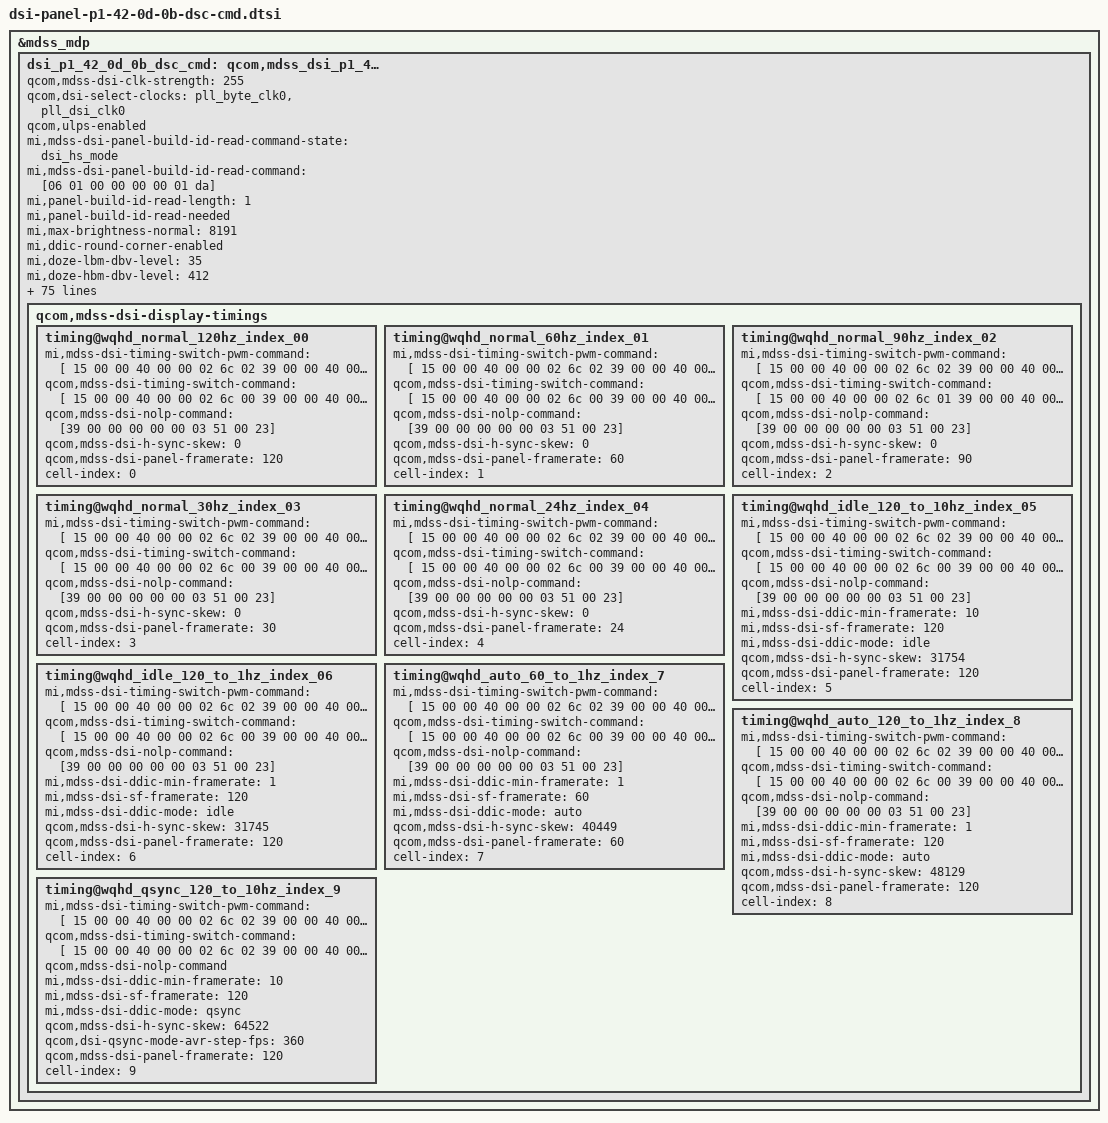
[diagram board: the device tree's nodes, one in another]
/* Xiaomi 17 Ultra panel configuration, OS4.0.7.0.XPACNXM. */

&mdss_mdp {
	dsi_p1_42_0d_0b_dsc_cmd: qcom,mdss_dsi_p1_42_0d_0b_dsc_cmd {
		qcom,mdss-dsi-clk-strength = <255>;
		qcom,dsi-select-clocks = "pll_byte_clk0", "pll_dsi_clk0";
		qcom,ulps-enabled;
		mi,mdss-dsi-panel-build-id-read-command-state = "dsi_hs_mode";
		mi,mdss-dsi-panel-build-id-read-command = [06 01 00 00 00 00 01 da];
		mi,panel-build-id-read-length = <1>;
		mi,panel-build-id-read-needed;
		mi,max-brightness-normal = <8191>;
		mi,ddic-round-corner-enabled;
		mi,doze-lbm-dbv-level = <35>;
		mi,doze-hbm-dbv-level = <412>;
		mi,mdss-dsi-panel-flatmode-on-status-value = <0>;
		mi,mdss-dsi-panel-flatmode-status-read-length = <1>;
		mi,mdss-dsi-panel-flatmode-status-command-state = "dsi_hs_mode";
		mi,mdss-dsi-panel-flatmode-status-command = [06 01 00 01 00 00 01 5f];
		mi,flatmode-status-check-enabled;
		mi,mdss-fac-brightness-max-level = <8191>;
		mi,mdss-dsi-fac-bl-max-level = <8191>;
		mi,mdss-dsi-panel-cell-id-read-length = <13>;
		mi,mdss-dsi-panel-cell-id-read-command-state = "dsi_hs_mode";
		mi,mdss-dsi-panel-cell-id-read-command = [06 01 00 00 00 00 01 5a];
		mi,mdss-dsi-panel-wp-read-length = <8>;
		mi,mdss-dsi-panel-wp-read-command-state = "dsi_hs_mode";
		mi,mdss-dsi-panel-wp-read-command = [06 01 00 00 00 00 01 5c];
		mi,esd-err-irq-gpio-flag = <8196>;
		mi,esd-err-irq-gpio = <&tlmm 97 8196>;
		mi,default-dc-flag;
		mi,dc-feature-enabled;
		mi,panel-on-dimming-delay = <120>;
		mi,dsi-panel-backplane-technology = "LTPO";
		mi,panel-id = <20529 4328715>;
		qcom,platform-pmic-reset-gpio = <&tlmm 171 0>;
		qcom,platform-reset-gpio = <&tlmm 98 0>;
		qcom,mdss-brightness-init-level = <916>;
		qcom,mdss-brightness-max-level = <16383>;
		qcom,bl-dsc-cmd-state = "dsi_hs_mode";
		qcom,mdss-dsi-bl-max-level = <16383>;
		qcom,mdss-dsi-bl-min-level = <7>;
		qcom,mdss-dsi-bl-pmic-control-type = "bl_ctrl_dcs";
		qcom,panel-supply-entries = <&dsi_panel_pwr_supply_p1_0b>;
		qcom,mdss-disable-cesta-hw-sleep;
		qcom,mdss-dsi-dma-schedule-window = <50>;
		qcom,mdss-dsi-dma-schedule-line = <1>;
		qcom,mdss-dsi-panel-blackness-level = <3230>;
		qcom,mdss-dsi-panel-peak-brightness = <32000000>;
		qcom,mdss-dsi-panel-hdr-color-primaries = <14500 15500 32000 17000 15500 30000 8000 3000>;
		qcom,mdss-dsi-panel-hdr-enabled;
		qcom,bl-update-flag = "delay_until_first_frame";
		qcom,mdss-dsi-bl-inverted-dbv;
		qcom,mdss-dsi-lp11-init;
		qcom,mdss-dsi-tx-eot-append;
		qcom,mdss-dsi-te-dcs-command = <1>;
		qcom,mdss-dsi-wr-mem-continue = <60>;
		qcom,mdss-dsi-wr-mem-start = <44>;
		qcom,mdss-dsi-te-pin-select = <1>;
		qcom,mdss-pan-physical-height-dimension = <1580>;
		qcom,mdss-pan-physical-width-dimension = <727>;
		qcom,mdss-dsi-reset-sequence = <1 1 0 1 1 10>;
		qcom,mdss-dsi-mdp-trigger = "none";
		qcom,mdss-dsi-dma-trigger = "trigger_sw";
		qcom,mdss-dsi-color-order = "rgb_swap_rgb";
		qcom,mdss-dsi-lane-3-state;
		qcom,mdss-dsi-lane-2-state;
		qcom,mdss-dsi-lane-1-state;
		qcom,mdss-dsi-lane-0-state;
		qcom,mdss-dsi-bllp-power-mode;
		qcom,mdss-dsi-bllp-eof-power-mode;
		qcom,mdss-dsi-traffic-mode = "burst_mode";
		qcom,dsi-phy-num = <0>;
		qcom,dsi-ctrl-num = <0>;
		qcom,mdss-dsi-bpp = <30>;
		qcom,mdss-dsi-virtual-channel-id = <0>;
		qcom,mdss-dsi-panel-physical-type = "oled";
		qcom,mdss-dsi-panel-type = "dsi_cmd_mode";
		qcom,mdss-dsi-panel-name = "xiaomi p1 42 0d 0b prim cmd mode dsc dsi panel";

		qcom,mdss-dsi-display-timings {
			timing@wqhd_normal_120hz_index_00 {
				#include "dsi-panel-p1-42-0d-0b-dsc-cmd-common.dtsi"
				mi,mdss-dsi-timing-switch-pwm-command = [
					15 00 00 40 00 00 02 6c 02 39 00 00 40 00 00 03
					75 00 00 39 00 00 40 00 00 04 71 00 00 00 39 00
					00 40 00 00 03 f0 aa 16 15 00 00 40 00 00 02 d0
					00 15 00 00 40 00 00 02 65 07 15 00 00 40 00 00
					02 d1 02 15 00 00 40 00 00 02 d2 01 15 00 00 40
					00 00 02 65 02 39 00 00 40 00 00 04 d2 03 65 0f
					15 00 00 40 00 00 02 76 01 15 00 00 40 00 00 02
					77 05 39 00 00 40 00 00 03 f0 aa 10 15 00 00 40
					00 00 02 cf 09 39 00 00 00 00 00 03 f0 aa 00
				];
				qcom,mdss-dsi-timing-switch-command = [
					15 00 00 40 00 00 02 6c 00 39 00 00 40 00 00 03
					75 00 00 39 00 00 40 00 00 04 71 00 00 00 39 00
					00 40 00 00 03 f0 aa 16 15 00 00 40 00 00 02 d0
					00 15 00 00 40 00 00 02 65 01 15 00 00 40 00 00
					02 d1 00 15 00 00 40 00 00 02 d2 01 15 00 00 40
					00 00 02 76 00 15 00 00 40 00 00 02 77 00 39 00
					00 40 00 00 03 f0 aa 10 15 00 00 40 00 00 02 cf
					17 39 00 00 00 00 00 03 f0 aa 00
				];
				qcom,mdss-dsi-nolp-command = [39 00 00 00 00 00 03 51 00 23];
				qcom,mdss-dsi-h-sync-skew = <0>;
				qcom,mdss-dsi-panel-framerate = <120>;
				cell-index = <0>;
			};

			timing@wqhd_normal_60hz_index_01 {
				#include "dsi-panel-p1-42-0d-0b-dsc-cmd-common.dtsi"
				mi,mdss-dsi-timing-switch-pwm-command = [
					15 00 00 40 00 00 02 6c 02 39 00 00 40 00 00 03
					75 c0 00 39 00 00 40 00 00 04 71 01 00 01 39 00
					00 40 00 00 03 f0 aa 16 15 00 00 40 00 00 02 d0
					00 15 00 00 40 00 00 02 65 07 15 00 00 40 00 00
					02 d1 02 15 00 00 40 00 00 02 d2 01 15 00 00 40
					00 00 02 65 02 39 00 00 40 00 00 04 d2 03 65 0f
					15 00 00 40 00 00 02 76 01 15 00 00 40 00 00 02
					77 0b 39 00 00 40 00 00 03 f0 aa 10 15 00 00 40
					00 00 02 cf 09 39 00 00 00 00 00 03 f0 aa 00
				];
				qcom,mdss-dsi-timing-switch-command = [
					15 00 00 40 00 00 02 6c 00 39 00 00 40 00 00 03
					75 c0 00 39 00 00 40 00 00 04 71 01 00 01 39 00
					00 40 00 00 03 f0 aa 16 15 00 00 40 00 00 02 d0
					00 15 00 00 40 00 00 02 65 01 15 00 00 40 00 00
					02 d1 00 15 00 00 40 00 00 02 d2 01 15 00 00 40
					00 00 02 65 02 39 00 00 40 00 00 04 d2 0a 53 0f
					15 00 00 40 00 00 02 76 01 15 00 00 40 00 00 02
					77 03 39 00 00 40 00 00 03 f0 aa 10 15 00 00 40
					00 00 02 cf 09 39 00 00 00 00 00 03 f0 aa 00
				];
				qcom,mdss-dsi-nolp-command = [39 00 00 00 00 00 03 51 00 23];
				qcom,mdss-dsi-h-sync-skew = <0>;
				qcom,mdss-dsi-panel-framerate = <60>;
				cell-index = <1>;
			};

			timing@wqhd_normal_90hz_index_02 {
				#include "dsi-panel-p1-42-0d-0b-dsc-cmd-common.dtsi"
				mi,mdss-dsi-timing-switch-pwm-command = [
					15 00 00 40 00 00 02 6c 02 39 00 00 40 00 00 03
					75 c0 00 39 00 00 40 00 00 04 71 01 10 00 39 00
					00 40 00 00 03 f0 aa 16 15 00 00 40 00 00 02 d0
					00 15 00 00 40 00 00 02 65 07 15 00 00 40 00 00
					02 d1 02 15 00 00 40 00 00 02 d2 01 15 00 00 40
					00 00 02 65 02 39 00 00 40 00 00 04 d2 03 65 0f
					15 00 00 40 00 00 02 76 01 15 00 00 40 00 00 02
					77 07 39 00 00 40 00 00 03 f0 aa 10 15 00 00 40
					00 00 02 cf 09 39 00 00 00 00 00 03 f0 aa 00
				];
				qcom,mdss-dsi-timing-switch-command = [
					15 00 00 40 00 00 02 6c 01 39 00 00 40 00 00 03
					75 c0 06 39 00 00 40 00 00 04 71 00 00 00 39 00
					00 40 00 00 03 f0 aa 16 15 00 00 40 00 00 02 d0
					03 15 00 00 40 00 00 02 65 04 15 00 00 40 00 00
					02 d1 02 15 00 00 40 00 00 02 d2 01 15 00 00 40
					00 00 02 65 02 39 00 00 40 00 00 04 d2 0d ca 0f
					15 00 00 40 00 00 02 76 01 15 00 00 40 00 00 02
					77 01 39 00 00 40 00 00 03 f0 aa 10 15 00 00 40
					00 00 02 cf 09 39 00 00 00 00 00 03 f0 aa 00
				];
				qcom,mdss-dsi-nolp-command = [39 00 00 00 00 00 03 51 00 23];
				qcom,mdss-dsi-h-sync-skew = <0>;
				qcom,mdss-dsi-panel-framerate = <90>;
				cell-index = <2>;
			};

			timing@wqhd_normal_30hz_index_03 {
				#include "dsi-panel-p1-42-0d-0b-dsc-cmd-common.dtsi"
				mi,mdss-dsi-timing-switch-pwm-command = [
					15 00 00 40 00 00 02 6c 02 39 00 00 40 00 00 03
					75 c0 01 39 00 00 40 00 00 04 71 00 00 00 39 00
					00 40 00 00 03 f0 aa 16 15 00 00 40 00 00 02 d0
					00 15 00 00 40 00 00 02 65 07 15 00 00 40 00 00
					02 d1 05 15 00 00 40 00 00 02 d2 01 15 00 00 40
					00 00 02 65 02 39 00 00 40 00 00 04 d2 03 65 0f
					15 00 00 40 00 00 02 76 01 15 00 00 40 00 00 02
					77 17 39 00 00 40 00 00 03 f0 aa 10 15 00 00 40
					00 00 02 cf 09 39 00 00 00 00 00 03 f0 aa 00
				];
				qcom,mdss-dsi-timing-switch-command = [
					15 00 00 40 00 00 02 6c 00 39 00 00 40 00 00 03
					75 c0 01 39 00 00 40 00 00 04 71 00 00 00 39 00
					00 40 00 00 03 f0 aa 16 15 00 00 40 00 00 02 d0
					00 15 00 00 40 00 00 02 65 01 15 00 00 40 00 00
					02 d1 01 15 00 00 40 00 00 02 d2 01 15 00 00 40
					00 00 02 65 02 39 00 00 40 00 00 04 d2 0a 53 0f
					15 00 00 40 00 00 02 76 01 15 00 00 40 00 00 02
					77 07 39 00 00 40 00 00 03 f0 aa 10 15 00 00 40
					00 00 02 cf 09 39 00 00 00 00 00 03 f0 aa 00
				];
				qcom,mdss-dsi-nolp-command = [39 00 00 00 00 00 03 51 00 23];
				qcom,mdss-dsi-h-sync-skew = <0>;
				qcom,mdss-dsi-panel-framerate = <30>;
				cell-index = <3>;
			};

			timing@wqhd_normal_24hz_index_04 {
				#include "dsi-panel-p1-42-0d-0b-dsc-cmd-common.dtsi"
				mi,mdss-dsi-timing-switch-pwm-command = [
					15 00 00 40 00 00 02 6c 02 39 00 00 40 00 00 03
					75 c0 02 39 00 00 40 00 00 04 71 00 00 00 39 00
					00 40 00 00 03 f0 aa 16 15 00 00 40 00 00 02 d0
					00 15 00 00 40 00 00 02 65 07 15 00 00 40 00 00
					02 d1 0b 15 00 00 40 00 00 02 d2 01 15 00 00 40
					00 00 02 65 02 39 00 00 40 00 00 04 d2 03 65 0f
					15 00 00 40 00 00 02 76 01 15 00 00 40 00 00 02
					77 1d 39 00 00 40 00 00 03 f0 aa 10 15 00 00 40
					00 00 02 cf 09 39 00 00 00 00 00 03 f0 aa 00
				];
				qcom,mdss-dsi-timing-switch-command = [
					15 00 00 40 00 00 02 6c 00 39 00 00 40 00 00 03
					75 c0 02 39 00 00 40 00 00 04 71 00 00 00 39 00
					00 40 00 00 03 f0 aa 16 15 00 00 40 00 00 02 d0
					00 15 00 00 40 00 00 02 65 01 15 00 00 40 00 00
					02 d1 01 15 00 00 40 00 00 02 d2 01 15 00 00 40
					00 00 02 65 02 39 00 00 40 00 00 04 d2 0a 53 0f
					15 00 00 40 00 00 02 76 01 15 00 00 40 00 00 02
					77 09 39 00 00 40 00 00 03 f0 aa 10 15 00 00 40
					00 00 02 cf 09 39 00 00 00 00 00 03 f0 aa 00
				];
				qcom,mdss-dsi-nolp-command = [39 00 00 00 00 00 03 51 00 23];
				qcom,mdss-dsi-h-sync-skew = <0>;
				qcom,mdss-dsi-panel-framerate = <24>;
				cell-index = <4>;
			};

			timing@wqhd_idle_120_to_10hz_index_05 {
				#include "dsi-panel-p1-42-0d-0b-dsc-cmd-common.dtsi"
				mi,mdss-dsi-timing-switch-pwm-command = [
					15 00 00 40 00 00 02 6c 02 39 00 00 40 00 00 03
					75 c0 07 39 00 00 40 00 00 04 71 00 00 00 39 00
					00 40 00 00 03 f0 aa 16 15 00 00 40 00 00 02 d0
					03 15 00 00 40 00 00 02 65 07 15 00 00 40 00 00
					02 d1 0b 15 00 00 40 00 00 02 d2 01 15 00 00 40
					00 00 02 65 02 39 00 00 40 00 00 04 d2 03 65 0f
					15 00 00 40 00 00 02 76 01 15 00 00 40 00 00 02
					77 05 39 00 00 40 00 00 03 f0 aa 10 15 00 00 40
					00 00 02 cf 09 39 00 00 00 00 00 03 f0 aa 00
				];
				qcom,mdss-dsi-timing-switch-command = [
					15 00 00 40 00 00 02 6c 00 39 00 00 40 00 00 03
					75 c0 03 39 00 00 40 00 00 04 71 00 00 00 39 00
					00 40 00 00 03 f0 aa 16 15 00 00 40 00 00 02 d0
					03 15 00 00 40 00 00 02 65 01 15 00 00 40 00 00
					02 d1 01 15 00 00 40 00 00 02 d2 01 15 00 00 40
					00 00 02 65 02 39 00 00 40 00 00 04 d2 0a 53 0f
					15 00 00 40 00 00 02 76 01 15 00 00 40 00 00 02
					77 01 39 00 00 40 00 00 03 f0 aa 10 15 00 00 40
					00 00 02 cf 09 39 00 00 00 00 00 03 f0 aa 00
				];
				qcom,mdss-dsi-nolp-command = [39 00 00 00 00 00 03 51 00 23];
				mi,mdss-dsi-ddic-min-framerate = <10>;
				mi,mdss-dsi-sf-framerate = <120>;
				mi,mdss-dsi-ddic-mode = "idle";
				qcom,mdss-dsi-h-sync-skew = <31754>;
				qcom,mdss-dsi-panel-framerate = <120>;
				cell-index = <5>;
			};

			timing@wqhd_idle_120_to_1hz_index_06 {
				#include "dsi-panel-p1-42-0d-0b-dsc-cmd-common.dtsi"
				mi,mdss-dsi-timing-switch-pwm-command = [
					15 00 00 40 00 00 02 6c 02 39 00 00 40 00 00 03
					75 c0 05 39 00 00 40 00 00 04 71 00 00 00 39 00
					00 40 00 00 03 f0 aa 16 15 00 00 40 00 00 02 d0
					03 15 00 00 40 00 00 02 65 07 15 00 00 40 00 00
					02 d1 0b 15 00 00 40 00 00 02 d2 01 15 00 00 40
					00 00 02 65 02 39 00 00 40 00 00 04 d2 03 65 0f
					15 00 00 40 00 00 02 76 01 15 00 00 40 00 00 02
					77 05 39 00 00 40 00 00 03 f0 aa 10 15 00 00 40
					00 00 02 cf 09 39 00 00 00 00 00 03 f0 aa 00
				];
				qcom,mdss-dsi-timing-switch-command = [
					15 00 00 40 00 00 02 6c 00 39 00 00 40 00 00 03
					75 c0 04 39 00 00 40 00 00 04 71 00 00 00 39 00
					00 40 00 00 03 f0 aa 16 15 00 00 40 00 00 02 d0
					03 15 00 00 40 00 00 02 65 01 15 00 00 40 00 00
					02 d1 01 15 00 00 40 00 00 02 d2 01 15 00 00 40
					00 00 02 65 02 39 00 00 40 00 00 04 d2 0a 53 0f
					15 00 00 40 00 00 02 76 01 15 00 00 40 00 00 02
					77 01 39 00 00 40 00 00 03 f0 aa 10 15 00 00 40
					00 00 02 cf 09 39 00 00 00 00 00 03 f0 aa 00
				];
				qcom,mdss-dsi-nolp-command = [39 00 00 00 00 00 03 51 00 23];
				mi,mdss-dsi-ddic-min-framerate = <1>;
				mi,mdss-dsi-sf-framerate = <120>;
				mi,mdss-dsi-ddic-mode = "idle";
				qcom,mdss-dsi-h-sync-skew = <31745>;
				qcom,mdss-dsi-panel-framerate = <120>;
				cell-index = <6>;
			};

			timing@wqhd_auto_60_to_1hz_index_7 {
				#include "dsi-panel-p1-42-0d-0b-dsc-cmd-common.dtsi"
				mi,mdss-dsi-timing-switch-pwm-command = [
					15 00 00 40 00 00 02 6c 02 39 00 00 40 00 00 03
					75 c0 05 39 00 00 40 00 00 04 71 00 00 00 39 00
					00 40 00 00 03 f0 aa 16 15 00 00 40 00 00 02 d0
					01 15 00 00 40 00 00 02 65 07 15 00 00 40 00 00
					02 d1 0b 15 00 00 40 00 00 02 d2 01 15 00 00 40
					00 00 02 65 02 39 00 00 40 00 00 04 d2 03 65 0f
					15 00 00 40 00 00 02 76 01 15 00 00 40 00 00 02
					77 0b 39 00 00 40 00 00 03 f0 aa 10 15 00 00 40
					00 00 02 cf 09 39 00 00 00 00 00 03 f0 aa 00
				];
				qcom,mdss-dsi-timing-switch-command = [
					15 00 00 40 00 00 02 6c 00 39 00 00 40 00 00 03
					75 c0 05 39 00 00 40 00 00 04 71 00 00 00 39 00
					00 40 00 00 03 f0 aa 16 15 00 00 40 00 00 02 d0
					01 15 00 00 40 00 00 02 65 01 15 00 00 40 00 00
					02 d1 03 15 00 00 40 00 00 02 d2 01 15 00 00 40
					00 00 02 65 02 39 00 00 40 00 00 04 d2 0a 53 0f
					15 00 00 40 00 00 02 76 01 15 00 00 40 00 00 02
					77 03 39 00 00 40 00 00 03 f0 aa 10 15 00 00 40
					00 00 02 cf 09 39 00 00 00 00 00 03 f0 aa 00
				];
				qcom,mdss-dsi-nolp-command = [39 00 00 00 00 00 03 51 00 23];
				mi,mdss-dsi-ddic-min-framerate = <1>;
				mi,mdss-dsi-sf-framerate = <60>;
				mi,mdss-dsi-ddic-mode = "auto";
				qcom,mdss-dsi-h-sync-skew = <40449>;
				qcom,mdss-dsi-panel-framerate = <60>;
				cell-index = <7>;
			};

			timing@wqhd_auto_120_to_1hz_index_8 {
				#include "dsi-panel-p1-42-0d-0b-dsc-cmd-common.dtsi"
				mi,mdss-dsi-timing-switch-pwm-command = [
					15 00 00 40 00 00 02 6c 02 39 00 00 40 00 00 03
					75 c0 05 39 00 00 40 00 00 04 71 00 00 00 39 00
					00 40 00 00 03 f0 aa 16 15 00 00 40 00 00 02 d0
					03 15 00 00 40 00 00 02 65 07 15 00 00 40 00 00
					02 d1 0b 15 00 00 40 00 00 02 d2 01 15 00 00 40
					00 00 02 65 02 39 00 00 40 00 00 04 d2 03 65 0f
					15 00 00 40 00 00 02 76 01 15 00 00 40 00 00 02
					77 05 39 00 00 40 00 00 03 f0 aa 10 15 00 00 40
					00 00 02 cf 09 39 00 00 00 00 00 03 f0 aa 00
				];
				qcom,mdss-dsi-timing-switch-command = [
					15 00 00 40 00 00 02 6c 00 39 00 00 40 00 00 03
					75 c0 04 39 00 00 40 00 00 04 71 00 00 00 39 00
					00 40 00 00 03 f0 aa 16 15 00 00 40 00 00 02 d0
					03 15 00 00 40 00 00 02 65 01 15 00 00 40 00 00
					02 d1 01 15 00 00 40 00 00 02 d2 01 15 00 00 40
					00 00 02 65 02 39 00 00 40 00 00 04 d2 0a 53 0f
					15 00 00 40 00 00 02 76 01 15 00 00 40 00 00 02
					77 01 39 00 00 40 00 00 03 f0 aa 10 15 00 00 40
					00 00 02 cf 09 39 00 00 00 00 00 03 f0 aa 00
				];
				qcom,mdss-dsi-nolp-command = [39 00 00 00 00 00 03 51 00 23];
				mi,mdss-dsi-ddic-min-framerate = <1>;
				mi,mdss-dsi-sf-framerate = <120>;
				mi,mdss-dsi-ddic-mode = "auto";
				qcom,mdss-dsi-h-sync-skew = <48129>;
				qcom,mdss-dsi-panel-framerate = <120>;
				cell-index = <8>;
			};

			timing@wqhd_qsync_120_to_10hz_index_9 {
				#include "dsi-panel-p1-42-0d-0b-dsc-cmd-common.dtsi"
				mi,mdss-dsi-timing-switch-pwm-command = [
					15 00 00 40 00 00 02 6c 02 39 00 00 40 00 00 03
					75 c0 07 39 00 00 40 00 00 04 71 00 00 00 39 00
					00 40 00 00 03 f0 aa 16 15 00 00 40 00 00 02 d0
					01 15 00 00 40 00 00 02 65 07 15 00 00 40 00 00
					02 d1 0b 15 00 00 40 00 00 02 d2 02 15 00 00 40
					00 00 02 76 00 15 00 00 40 00 00 02 77 00 39 00
					00 40 00 00 03 f0 aa 10 15 00 00 40 00 00 02 cf
					17 39 00 00 00 00 00 03 f0 aa 00
				];
				qcom,mdss-dsi-timing-switch-command = [
					15 00 00 40 00 00 02 6c 02 39 00 00 40 00 00 03
					75 c0 07 39 00 00 40 00 00 04 71 00 00 00 39 00
					00 40 00 00 03 f0 aa 16 15 00 00 40 00 00 02 d0
					01 15 00 00 40 00 00 02 65 07 15 00 00 40 00 00
					02 d1 0b 15 00 00 40 00 00 02 d2 02 15 00 00 40
					00 00 02 76 00 15 00 00 40 00 00 02 77 00 39 00
					00 40 00 00 03 f0 aa 10 15 00 00 40 00 00 02 cf
					17 39 00 00 00 00 00 03 f0 aa 00
				];
				qcom,mdss-dsi-nolp-command;
				mi,mdss-dsi-ddic-min-framerate = <10>;
				mi,mdss-dsi-sf-framerate = <120>;
				mi,mdss-dsi-ddic-mode = "qsync";
				qcom,mdss-dsi-h-sync-skew = <64522>;
				qcom,dsi-qsync-mode-avr-step-fps = <360>;
				qcom,mdss-dsi-panel-framerate = <120>;
				cell-index = <9>;
			};
		};
	};
};
